# AST1060 register map
File version: 1.0
CPU: CM4 r0p1, little endian, MPU, FPU, 4 interrupt priority bits, 256 interrupts
Registers are 32-bit, read-write, reset 0x0 unless marked. A register's access mark holds for its fields unless they carry their own. Offsets are from the block's base; [hi:lo] are bit positions; {n}, {i} and the like mark numbered series; 'fields as' and 'values as' point back to an identical list.

## i3c
Base 0x7E7A2000
Same registers: i3c1 0x7E7A3000, i3c2 0x7E7A4000, i3c3 0x7E7A5000
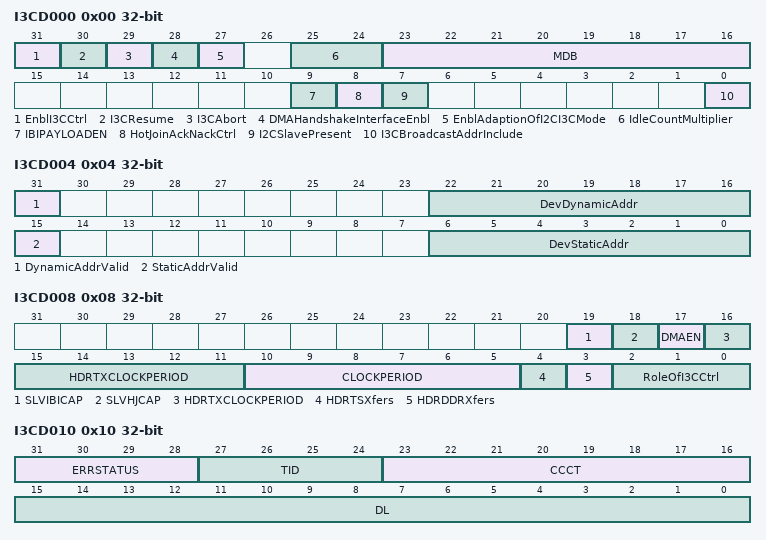
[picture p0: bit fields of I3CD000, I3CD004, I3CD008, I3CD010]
0x00 I3CD000 — Devicee Control Register
  [31] EnblI3CCtrl — Controls whether I3C is enabled in master mode of operation
  [30] I3CResume
  [29] I3CAbort
  [28] DMAHandshakeInterfaceEnbl — DMA Handshake Interface Enable.
  [27] EnblAdaptionOfI2CI3CMode — Control bit to enable the controller to adapt to I2C/I3C mode of operation.
  [25:24] IdleCountMultiplier
  [23:16] MDB — Mandatory Byte in Slave Mode
  [9] IBIPAYLOADEN — Enable IBI with Data in Slave Mode
  [8] HotJoinAckNackCtrl — Hot-Join Ack/Nack Control
  [7] I2CSlavePresent
  [0] I3CBroadcastAddrInclude — I3C Broadcast Address include.
0x04 I3CD004 — Device Address Register
  [31] DynamicAddrValid — Dynamic Address Valid
  [22:16] DevDynamicAddr — Device Dynamic Address
  [15] StaticAddrValid — Static Address Valid
  [6:0] DevStaticAddr — Device Static Address.
0x08 I3CD008 — Hardware Capability register
  [19] SLVIBICAP ro — Specifies slave's capability to initiate slave interrupt requests. n
  [18] SLVHJCAP ro — Specifies slave's capability to initiate Hot-join request n
  [17] DMAEN ro — Specifies whether controller is configured to have DMA handshaking interface. n
  [16:11] HDRTXCLOCKPERIOD ro — Reflects the IC_HDR_TX_CLK_PERIOD Configurable Parameter. n
  [10:5] CLOCKPERIOD ro — Reflects the IC_CLK_PERIOD Configurable Parameter
  [4] HDRTSXfers ro — HDR-TS transfers
  [3] HDRDDRXfers ro — HDR-DDR transfers
  [2:0] RoleOfI3CCtrl ro — Role of I3C controller
0x0C I3CD00C — COMMAND\_QUEUE\_PORT
  [31:0] 32BitCmd — 32 bit command
0x10 I3CD010 — Response Queue
  [31:28] ERRSTATUS ro, [27:24] TID ro, [23:16] CCCT ro, [15:0] DL ro
0x14 I3CD014 — Receive/Transmit Data Port Register
  [31:0] RxDataPort ro — Receive Data Port
  [31:0] TxDataPort — Transmit Data Port
0x18 I3CD018 (reset mask 0xC100FFFF) — In-Band Interrupt Queue Data Register
  [31] IBIStatus ro
  [30] ERROR ro
  [24] LASTSTATUS ro
  [15:8] IBIIdentifier ro
  [31:0] InBandINTData ro — In-Band Interrupt Data
  [7:0] InBandINTDataLen ro — In-Band Interrupt data length
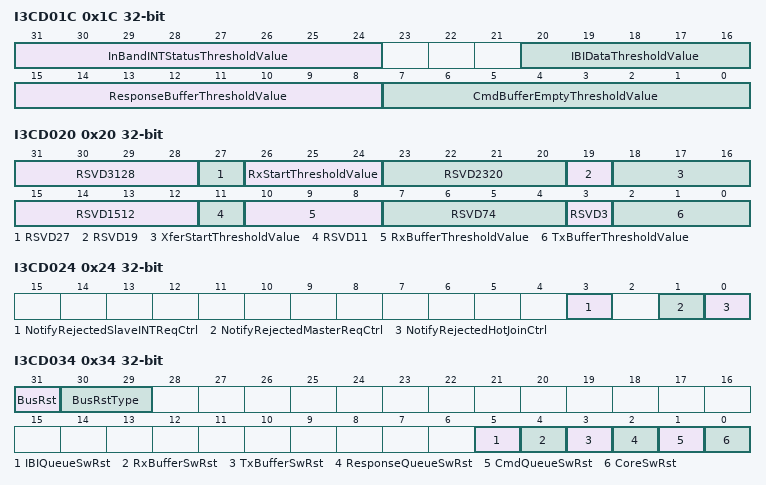
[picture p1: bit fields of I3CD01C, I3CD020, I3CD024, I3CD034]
0x1C I3CD01C — Queue Threshold Control Register
  [31:24] InBandINTStatusThresholdValue — In-Band Interrupt Status Threshold Value.
  [20:16] IBIDataThresholdValue
  [15:8] ResponseBufferThresholdValue
  [7:0] CmdBufferEmptyThresholdValue — Command Buffer Empty Threshold Value.
0x20 I3CD020 (reset mask 0x7070707) — Data Buffer Threshold Control Register
  [31:28] RSVD3128 ro — These bits in Data Buffer Threshold Control register are reserved.
  [27] RSVD27 ro — These bits in Data Buffer Threshold Control register are reserved.
  [26:24] RxStartThresholdValue — Receive Start Threshold Value.
  [23:20] RSVD2320 ro — These bits in Data Buffer Threshold Control Register are reserved.
  [19] RSVD19 ro — These bits in Data Buffer Threshold Control Register are reserved.
  [18:16] XferStartThresholdValue — Transfer Start Threshold Value.
  [15:12] RSVD1512 ro — These bits in Data Buffer Threshold Control Register are reserved.
  [11] RSVD11 ro — These bits in Data Buffer Threshold Control register are reserved.
  [10:8] RxBufferThresholdValue — Receive Buffer Threshold Value.
  [7:4] RSVD74 ro — These bits in Data Buffer Threshold Control Register are reserved.
  [3] RSVD3 ro — These bits in Data Buffer Threshold Control register are reserved.
  [2:0] TxBufferThresholdValue — Transmit Buffer Threshold Value.
0x24 I3CD024 — IBI Queue Control Register
  [3] NotifyRejectedSlaveINTReqCtrl — Notify Rejected Slave Interrupt Request Control
  [1] NotifyRejectedMasterReqCtrl — Notify Rejected Master Request Control.
  [0] NotifyRejectedHotJoinCtrl — Notify Rejected Hot-Join Control.
0x2C I3CD02C — IBI MR Request Rejection Control Register
  [31:0] InbandMasterReqReject — In-band Master Request Reject.
0x30 I3CD030 — IBI SIR Request Rejection Control Register
  [31:0] InbandSlaveINTReqReject — In-band Slave Interrupt Request Reject.
0x34 I3CD034 — Reset Control Register
  [31] BusRst ro — Bus Reset.
  [30:29] BusRstType ro — Bus Reset type
  [5] IBIQueueSwRst — IBI Queue Software Reset
  [4] RxBufferSwRst — Receive Buffer Software Reset.
  [3] TxBufferSwRst — Transmit Buffer Software Reset.
  [2] ResponseQueueSwRst — Response Queue Software Reset.
  [1] CmdQueueSwRst — Command Queue Software Reset.
  [0] CoreSwRst — Core Software Reset.
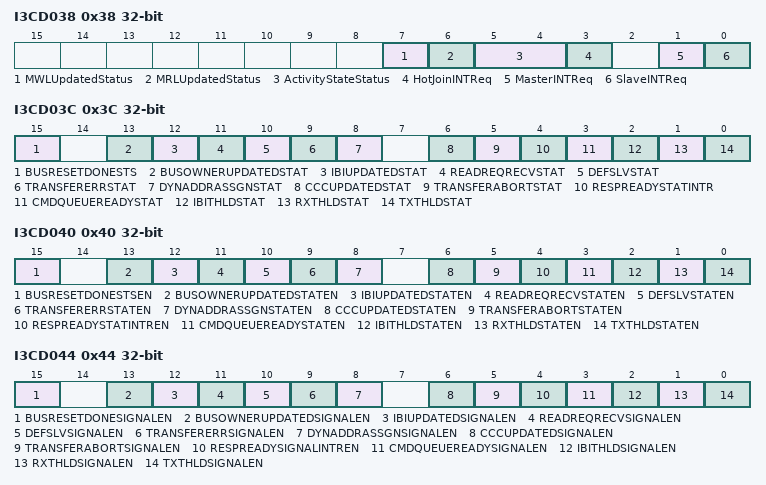
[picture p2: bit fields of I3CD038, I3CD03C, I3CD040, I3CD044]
0x38 I3CD038 — Slave Event Control Register
  [7] MWLUpdatedStatus
  [6] MRLUpdatedStatus
  [5:4] ActivityStateStatus ro
  [3] HotJoinINTReq ro — Hot-Join Interrupt Request.
  [1] MasterINTReq ro — Master Interrupt Request.
  [0] SlaveINTReq ro — Slave Interrupt Request.
0x3C I3CD03C — Interrupt Status Register
  [15] BUSRESETDONESTS, [13] BUSOWNERUPDATEDSTAT, [12] IBIUPDATEDSTAT, [11] READREQRECVSTAT, [10] DEFSLVSTAT, [9] TRANSFERERRSTAT, [8] DYNADDRASSGNSTAT, [6] CCCUPDATEDSTAT, [5] TRANSFERABORTSTAT, [4] RESPREADYSTATINTR, [3] CMDQUEUEREADYSTAT, [2] IBITHLDSTAT, [1] RXTHLDSTAT, [0] TXTHLDSTAT
0x40 I3CD040 — Interrupt Status Enable Register
  [15] BUSRESETDONESTSEN, [13] BUSOWNERUPDATEDSTATEN, [12] IBIUPDATEDSTATEN, [11] READREQRECVSTATEN, [10] DEFSLVSTATEN, [9] TRANSFERERRSTATEN, [8] DYNADDRASSGNSTATEN, [6] CCCUPDATEDSTATEN, [5] TRANSFERABORTSTATEN, [4] RESPREADYSTATINTREN, [3] CMDQUEUEREADYSTATEN, [2] IBITHLDSTATEN, [1] RXTHLDSTATEN, [0] TXTHLDSTATEN
0x44 I3CD044 — Interrupt Signal Enable Register
  [15] BUSRESETDONESIGNALEN, [13] BUSOWNERUPDATEDSIGNALEN, [12] IBIUPDATEDSIGNALEN, [11] READREQRECVSIGNALEN, [10] DEFSLVSIGNALEN, [9] TRANSFERERRSIGNALEN, [8] DYNADDRASSGNSIGNALEN, [6] CCCUPDATEDSIGNALEN, [5] TRANSFERABORTSIGNALEN, [4] RESPREADYSIGNALINTREN, [3] CMDQUEUEREADYSIGNALEN, [2] IBITHLDSIGNALEN, [1] RXTHLDSIGNALEN, [0] TXTHLDSIGNALEN
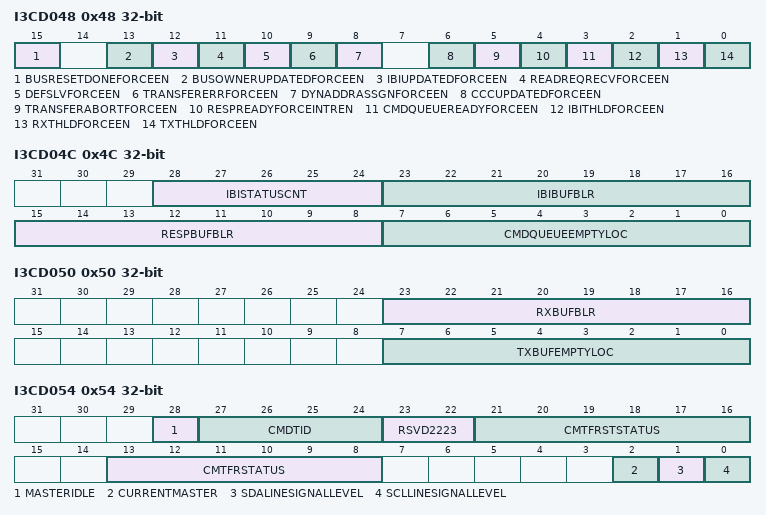
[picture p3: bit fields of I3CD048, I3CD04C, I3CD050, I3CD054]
0x48 I3CD048 — Interrupt Force Enable Register
  [15] BUSRESETDONEFORCEEN, [13] BUSOWNERUPDATEDFORCEEN, [12] IBIUPDATEDFORCEEN, [11] READREQRECVFORCEEN, [10] DEFSLVFORCEEN, [9] TRANSFERERRFORCEEN, [8] DYNADDRASSGNFORCEEN, [6] CCCUPDATEDFORCEEN, [5] TRANSFERABORTFORCEEN, [4] RESPREADYFORCEINTREN, [3] CMDQUEUEREADYFORCEEN, [2] IBITHLDFORCEEN, [1] RXTHLDFORCEEN, [0] TXTHLDFORCEEN
0x4C I3CD04C (reset mask 0x7FFFF) — QUEUE STATUS LEVEL Register
  [28:24] IBISTATUSCNT ro, [23:16] IBIBUFBLR ro, [15:8] RESPBUFBLR ro, [7:0] CMDQUEUEEMPTYLOC ro
0x50 I3CD050 — DATA BUFFER STATUS LEVEL Register
  [23:16] RXBUFBLR ro, [7:0] TXBUFEMPTYLOC ro
0x54 I3CD054 — PRESENT STATE Register
  [28] MASTERIDLE ro, [27:24] CMDTID ro, [23:22] RSVD2223 ro, [21:16] CMTFRSTSTATUS ro, [13:8] CMTFRSTATUS ro, [2] CURRENTMASTER ro, [1] SDALINESIGNALLEVEL ro, [0] SCLLINESIGNALLEVEL ro
0x58 I3CD058 — Device Operating Status Register
  [13] FRAMEERROR ro, [12] BUFFERNOTAVAIL ro, [11] DATANOTREADY ro, [10] OVERFLOWERR ro, [10] UNDERERR ro, [9] SLAVEBUSY ro, [7:6] ACTIVITYMODE ro, [7:6] PROTOCOLERR ro, [3:0] PENDINGINTR ro
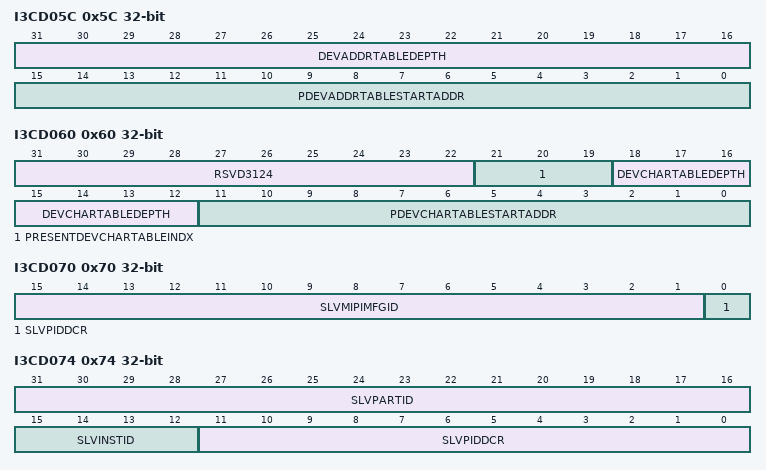
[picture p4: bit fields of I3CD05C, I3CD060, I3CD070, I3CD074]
0x5C I3CD05C — Pointer for Device Address Table Registers
  [31:16] DEVADDRTABLEDEPTH ro, [15:0] PDEVADDRTABLESTARTADDR ro
0x60 I3CD060 — Pointer for Device Characteristics Table
  [31:22] RSVD3124 ro, [21:19] PRESENTDEVCHARTABLEINDX, [18:12] DEVCHARTABLEDEPTH ro, [11:0] PDEVCHARTABLESTARTADDR ro
0x6C I3CD06C — Pointer for Vendor specific Registers.
  [15:0] PVENDORREGSTARTADDR ro
0x70 I3CD070 — Provisional ID Register.
  [15:1] SLVMIPIMFGID, [0] SLVPIDDCR
0x74 I3CD074 — Provisional ID Register.
  [31:16] SLVPARTID ro, [15:12] SLVINSTID, [11:0] SLVPIDDCR ro
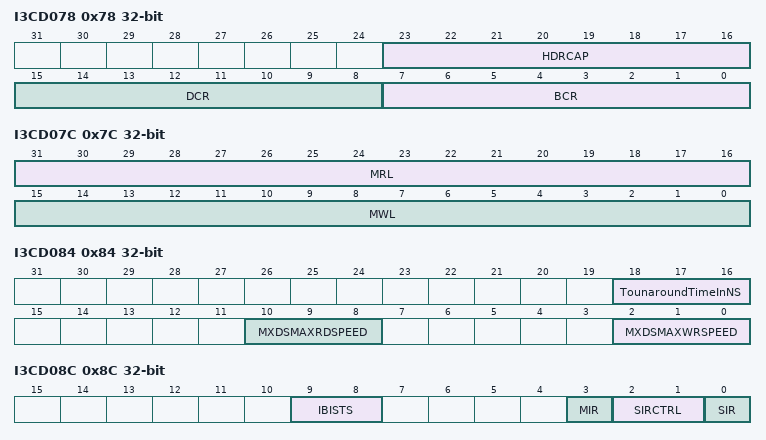
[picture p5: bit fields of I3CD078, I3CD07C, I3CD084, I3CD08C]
0x78 I3CD078 — I3C Slave Characteristic Register
  [23:16] HDRCAP ro, [15:8] DCR ro, [7:0] BCR ro
0x7C I3CD07C — I3C Max Write/Read Length Register
  [31:16] MRL ro, [15:0] MWL ro
0x80 I3CD080 — MXDS Maximum Read Turnaround Time Register
  [23:0] MXDSMAXRDTURN ro
0x84 I3CD084 — MXDS Maximum Data Speed Register
  [18:16] TounaroundTimeInNS, [10:8] MXDSMAXRDSPEED, [2:0] MXDSMAXWRSPEED
0x8C I3CD08C — Slave Interrupt Request Register
  [9:8] IBISTS ro, [3] MIR, [2:1] SIRCTRL, [0] SIR
0x90 I3CD090 — TSP/TSL Symbol Timing Register
  [5:0] SLVTSXSYMBLCNT
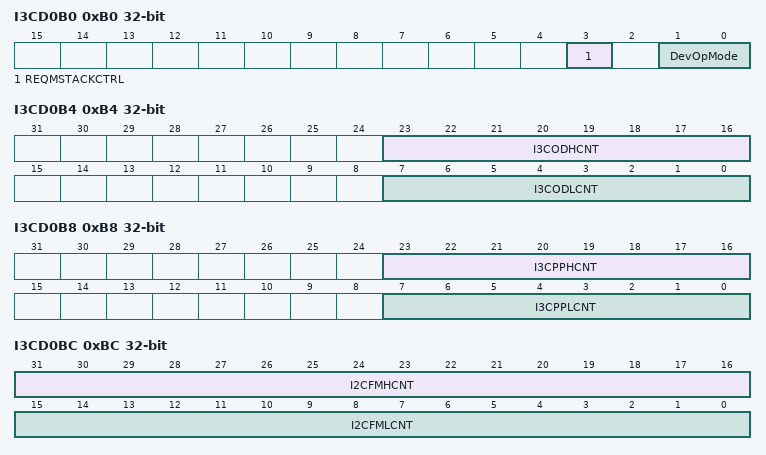
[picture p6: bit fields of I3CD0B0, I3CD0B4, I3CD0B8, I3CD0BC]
0xB0 I3CD0B0 — Device Control Extended Register
  [3] REQMSTACKCTRL
  [1:0] DevOpMode — Device Operation Mode
0xB4 I3CD0B4 — SCL I3C Open Drain Timing Register
  [23:16] I3CODHCNT, [7:0] I3CODLCNT
0xB8 I3CD0B8 — SCL I3C Push Pull Timing Register
  [23:16] I3CPPHCNT, [7:0] I3CPPLCNT
0xBC I3CD0BC — SCL I2C Fast Mode Timing Register
  [31:16] I2CFMHCNT, [15:0] I2CFMLCNT
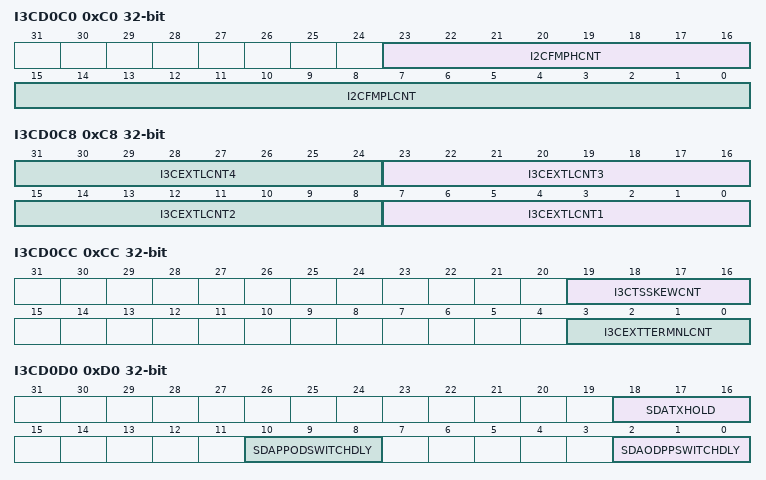
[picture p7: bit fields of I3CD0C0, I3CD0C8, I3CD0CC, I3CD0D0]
0xC0 I3CD0C0 — SCL I2C Fast Mode Plus Timing Register
  [23:16] I2CFMPHCNT, [15:0] I2CFMPLCNT
0xC8 I3CD0C8 — SCL Extended Low Count Timing Register
  [8n-1:8n-8] I3CEXTLCNT{n} (n=1..4)
0xCC I3CD0CC — SCL Termination Bit Low count Timing Register
  [19:16] I3CTSSKEWCNT, [3:0] I3CEXTTERMNLCNT
0xD0 I3CD0D0 — SDA Hold and Mode Switch Delay Timing Register
  [18:16] SDATXHOLD, [10:8] SDAPPODSWITCHDLY, [2:0] SDAODPPSWITCHDLY
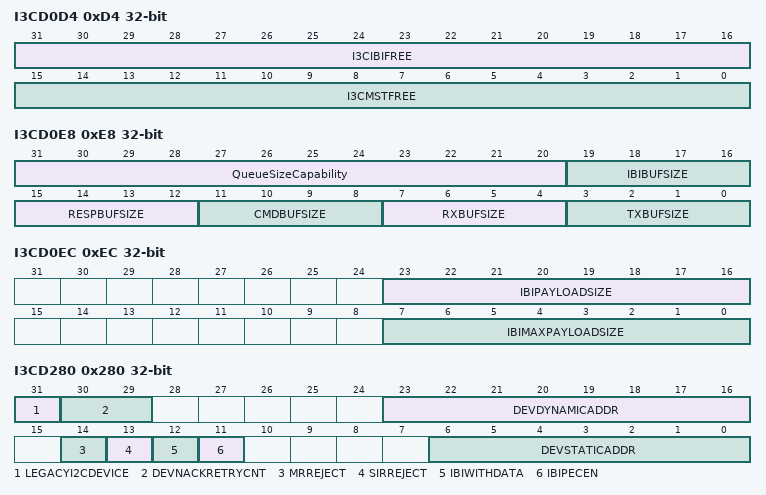
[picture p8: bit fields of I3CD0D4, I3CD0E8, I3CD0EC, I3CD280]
0xD4 I3CD0D4 — Bus Free Timing Register
  [31:16] I3CIBIFREE, [15:0] I3CMSTFREE
0xD8 I3CD0D8 — Bus Idle Timing Register
  [19:0] BUSIDLETIME
0xDC I3CD0DC — SCL Low Master Extended Timeout Register
  [25:0] SCLLOWMSTTIMEOUTCOUNT
0xE0 I3CD0E0 — I3C Version ID Register
  [31:0] I3CVersionID ro
0xE4 I3CD0E4 — I3C Version TYPE Register
  [31:0] I3CVERTYPE ro
0xE8 I3CD0E8 — I3C Queue Size Capability Register
  [31:20] QueueSizeCapability ro, [19:16] IBIBUFSIZE ro, [15:12] RESPBUFSIZE ro, [11:8] CMDBUFSIZE ro, [7:4] RXBUFSIZE ro, [3:0] TXBUFSIZE ro
0xEC I3CD0EC — I3C IBI Payload Length Register
  [23:16] IBIPAYLOADSIZE, [7:0] IBIMAXPAYLOADSIZE ro
0x200 I3CD200 — Device Characteristic Table Location-1 of Device1 (Master Mode)
  [31:24] STATICADDR ro, [23:16] BCRTYPE ro, [15:8] DCRTYPE ro, [31:0] LSBPROVISIONALID ro, [7:0] DYNAMICADDR ro
0x204 I3CD204 (reset mask 0xFFFF) — Device Characteristic Table Location-2 of Device1 (Master Mode)
  [31:24] STATICADDR ro, [23:16] BCRTYPE ro, [15:8] DCRTYPE ro, [15:0] MSBPROVISIONALID ro, [7:0] DYNAMICADDR ro
0x208 I3CD208 (reset mask 0xFFFF) — Device Characteristic Table Location-3 of Device1 (Master Mode)
  [31:24] STATICADDR ro, [23:16] BCRTYPE ro, [15:8] BCR ro, [15:8] DCRTYPE ro, [7:0] DCR ro, [7:0] DYNAMICADDR ro
0x20C I3CD20C (reset mask 0xFF) — Device Characteristic Table Location-4 of Device1 (Master Mode)
  [31:24] STATICADDR ro, [23:16] BCRTYPE ro, [15:8] DCRTYPE ro, [7:0] DEVDYNAMICADDR ro, [7:0] DYNAMICADDR ro
0x210 I3CD210 — Device Characteristic Table Location-1 of Device2 (Master Mode)
  fields as I3CD200
0x214 I3CD214 (reset mask 0xFFFF) — Device Characteristic Table Location-2 of Device2 (Master Mode)
  fields as I3CD204
0x218 I3CD218 (reset mask 0xFFFF) — Device Characteristic Table Location-2 of Device3 (Master Mode)
  fields as I3CD208
0x21C I3CD21C (reset mask 0xFF) — Device Characteristic Table Location-2 of Device4 (Master Mode)
  fields as I3CD20C
0x220 I3CD220 — Device Characteristic Table Location-1 of Device3 (Master Mode)
  fields as I3CD200
0x224 I3CD224 (reset mask 0xFFFF) — Device Characteristic Table Location-2 of Device3 (Master Mode)
  fields as I3CD204
0x228 I3CD228 (reset mask 0xFFFF) — Device Characteristic Table Location-3 of Device3 (Master Mode)
  fields as I3CD208
{0xCC+0x10*i} I3CD{i}C (reset mask 0xFF) (i=22..27) — Device Characteristic Table Location-4 of Device{i-19} (Master Mode)
  fields as I3CD20C
0x230 I3CD230 — Device Characteristic Table Location-1 of Device4 (Master Mode)
  fields as I3CD200
0x234 I3CD234 (reset mask 0xFFFF) — Device Characteristic Table Location-2 of Device4 (Master Mode)
  fields as I3CD204
0x238 I3CD238 (reset mask 0xFFFF) — Device Characteristic Table Location-3 of Device4 (Master Mode)
  fields as I3CD208
0x240 I3CD240 — Device Characteristic Table Location-1 of Device5 (Master Mode)
  fields as I3CD200
0x244 I3CD244 (reset mask 0xFFFF) — Device Characteristic Table Location-2 of Device5 (Master Mode)
  fields as I3CD204
0x248 I3CD248 (reset mask 0xFFFF) — Device Characteristic Table Location-3 of Device5 (Master Mode)
  fields as I3CD208
0x250 I3CD250 — Device Characteristic Table Location-1 of Device6 (Master Mode)
  fields as I3CD200
0x254 I3CD254 (reset mask 0xFFFF) — Device Characteristic Table Location-2 of Device6 (Master Mode)
  fields as I3CD204
0x258 I3CD258 (reset mask 0xFFFF) — Device Characteristic Table Location-3 of Device6 (Master Mode)
  fields as I3CD208
0x260 I3CD260 — Device Characteristic Table Location-1 of Device7 (Master Mode)
  fields as I3CD200
0x264 I3CD264 (reset mask 0xFFFF) — Device Characteristic Table Location-2 of Device7 (Master Mode)
  fields as I3CD204
0x268 I3CD268 (reset mask 0xFFFF) — Device Characteristic Table Location-3 of Device7 (Master Mode)
  fields as I3CD208
0x270 I3CD270 — Device Characteristic Table Location-1 of Device8 (Master Mode)
  fields as I3CD200
0x274 I3CD274 (reset mask 0xFFFF) — Device Characteristic Table Location-2 of Device8 (Master Mode)
  fields as I3CD204
0x278 I3CD278 (reset mask 0xFFFF) — Device Characteristic Table Location-3 of Device8 (Master Mode)
  fields as I3CD208
0x280 I3CD280 — Device Address Table of Device1
  [31] LEGACYI2CDEVICE
  [30:29] DEVNACKRETRYCNT
  [23:16] DEVDYNAMICADDR
  [14] MRREJECT — In-Band Master Request Reject field is used to control, per device, whether to accept Master request from Devices.
  [13] SIRREJECT — In-Band Slave Interrupt Request Reject field is used to control, per device, whether to accept Master request from
  [12] IBIWITHDATA — Mandatory one or more data bytes follow the accepted IBI from the device. Data byte continuation is indicated by
  [11] IBIPECEN — Packet Error Check enabled for accepted IBI from the device. PEC byte is appended at the end of IBI data from the
  [6:0] DEVSTATICADDR
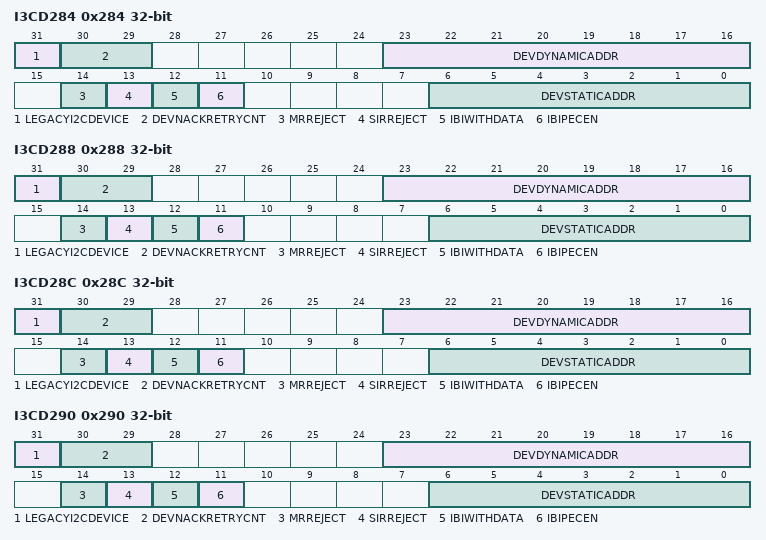
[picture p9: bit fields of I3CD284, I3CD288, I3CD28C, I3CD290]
0x284 I3CD284 — Device Address Table of Device2
  fields as I3CD280
0x288 I3CD288 — Device Address Table of Device3
  fields as I3CD280
0x28C I3CD28C — Device Address Table of Device4
  fields as I3CD280
0x290 I3CD290 — Device Address Table of Device5
  fields as I3CD280
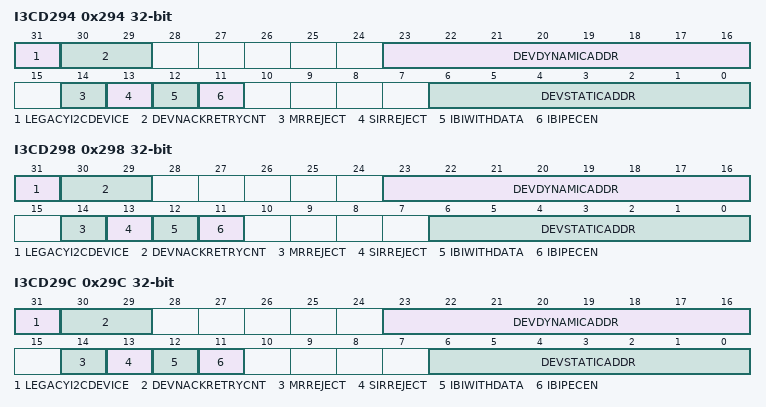
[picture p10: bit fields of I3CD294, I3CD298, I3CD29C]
0x294 I3CD294 — Device Address Table of Device6
  fields as I3CD280
0x298 I3CD298 — Device Address Table of Device7
  fields as I3CD280
0x29C I3CD29C — Device Address Table of Device8
  fields as I3CD280
